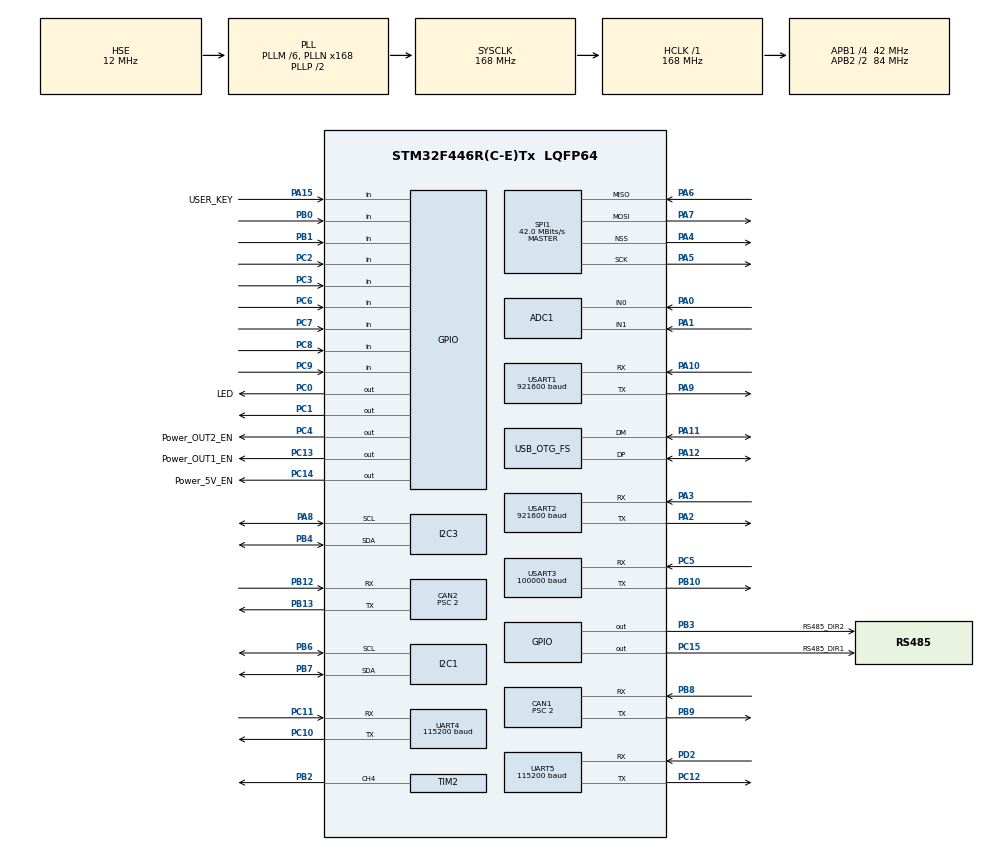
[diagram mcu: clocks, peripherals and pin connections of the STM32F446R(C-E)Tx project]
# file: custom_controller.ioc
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ADC1.Channel-0\#ChannelRegularConversion=ADC_CHANNEL_0
ADC1.NbrOfConversionFlag=1
ADC1.Rank-0\#ChannelRegularConversion=1
ADC1.SamplingTime-0\#ChannelRegularConversion=ADC_SAMPLETIME_3CYCLES
ADC1.master=1
CAN1.ABOM=ENABLE
CAN1.BS1=CAN_BS1_15TQ
CAN1.BS2=CAN_BS2_5TQ
CAN1.CalculateBaudRate=1000000
CAN1.CalculateTimeQuantum=47.61904761904762
CAN1.NART=ENABLE
CAN1.Prescaler=2
CAN1.SJW=CAN_SJW_1TQ
CAN2.ABOM=ENABLE
CAN2.BS1=CAN_BS1_15TQ
CAN2.BS2=CAN_BS2_5TQ
CAN2.CalculateBaudRate=1000000
CAN2.CalculateTimeBit=1000
CAN2.CalculateTimeQuantum=47.61904761904762
CAN2.NART=ENABLE
CAN2.Prescaler=2
CAN2.SJW=CAN_SJW_1TQ
Dma.Request0=USART1_RX
Dma.Request1=USART2_RX
Dma.Request2=UART4_RX
Dma.Request3=UART5_RX
Dma.Request4=USART3_RX
Dma.Request5=UART4_TX
Dma.UART4_RX.2.Direction=DMA_PERIPH_TO_MEMORY
Dma.UART4_RX.2.FIFOMode=DMA_FIFOMODE_DISABLE
Dma.UART4_RX.2.Instance=DMA1_Stream2
Dma.UART4_RX.2.MemDataAlignment=DMA_MDATAALIGN_BYTE
Dma.UART4_RX.2.MemInc=DMA_MINC_ENABLE
Dma.UART4_RX.2.Mode=DMA_NORMAL
Dma.UART4_RX.2.PeriphDataAlignment=DMA_PDATAALIGN_BYTE
Dma.UART4_RX.2.PeriphInc=DMA_PINC_DISABLE
Dma.UART4_RX.2.Priority=DMA_PRIORITY_MEDIUM
Dma.UART4_TX.5.Direction=DMA_MEMORY_TO_PERIPH
Dma.UART4_TX.5.FIFOMode=DMA_FIFOMODE_DISABLE
Dma.UART4_TX.5.Instance=DMA1_Stream4
Dma.UART4_TX.5.MemDataAlignment=DMA_MDATAALIGN_BYTE
Dma.UART4_TX.5.MemInc=DMA_MINC_ENABLE
Dma.UART4_TX.5.Mode=DMA_NORMAL
Dma.UART4_TX.5.PeriphDataAlignment=DMA_PDATAALIGN_BYTE
Dma.UART4_TX.5.PeriphInc=DMA_PINC_DISABLE
Dma.UART4_TX.5.Priority=DMA_PRIORITY_LOW
Dma.UART5_RX.3.Direction=DMA_PERIPH_TO_MEMORY
Dma.UART5_RX.3.FIFOMode=DMA_FIFOMODE_DISABLE
Dma.UART5_RX.3.Instance=DMA1_Stream0
Dma.UART5_RX.3.MemDataAlignment=DMA_MDATAALIGN_BYTE
Dma.UART5_RX.3.MemInc=DMA_MINC_ENABLE
Dma.UART5_RX.3.Mode=DMA_NORMAL
Dma.UART5_RX.3.PeriphDataAlignment=DMA_PDATAALIGN_BYTE
Dma.UART5_RX.3.PeriphInc=DMA_PINC_DISABLE
Dma.UART5_RX.3.Priority=DMA_PRIORITY_MEDIUM
Dma.USART1_RX.0.Direction=DMA_PERIPH_TO_MEMORY
Dma.USART1_RX.0.FIFOMode=DMA_FIFOMODE_DISABLE
Dma.USART1_RX.0.Instance=DMA2_Stream2
Dma.USART1_RX.0.MemDataAlignment=DMA_MDATAALIGN_BYTE
Dma.USART1_RX.0.MemInc=DMA_MINC_ENABLE
Dma.USART1_RX.0.Mode=DMA_NORMAL
Dma.USART1_RX.0.PeriphDataAlignment=DMA_PDATAALIGN_BYTE
Dma.USART1_RX.0.PeriphInc=DMA_PINC_DISABLE
Dma.USART1_RX.0.Priority=DMA_PRIORITY_HIGH
Dma.USART2_RX.1.Direction=DMA_PERIPH_TO_MEMORY
Dma.USART2_RX.1.FIFOMode=DMA_FIFOMODE_DISABLE
Dma.USART2_RX.1.Instance=DMA1_Stream5
Dma.USART2_RX.1.MemDataAlignment=DMA_MDATAALIGN_BYTE
Dma.USART2_RX.1.MemInc=DMA_MINC_ENABLE
Dma.USART2_RX.1.Mode=DMA_NORMAL
Dma.USART2_RX.1.PeriphDataAlignment=DMA_PDATAALIGN_BYTE
Dma.USART2_RX.1.PeriphInc=DMA_PINC_DISABLE
Dma.USART2_RX.1.Priority=DMA_PRIORITY_HIGH
Dma.USART3_RX.4.Direction=DMA_PERIPH_TO_MEMORY
Dma.USART3_RX.4.FIFOMode=DMA_FIFOMODE_DISABLE
Dma.USART3_RX.4.Instance=DMA1_Stream1
Dma.USART3_RX.4.MemDataAlignment=DMA_MDATAALIGN_BYTE
Dma.USART3_RX.4.MemInc=DMA_MINC_ENABLE
Dma.USART3_RX.4.Mode=DMA_NORMAL
Dma.USART3_RX.4.PeriphDataAlignment=DMA_PDATAALIGN_BYTE
Dma.USART3_RX.4.PeriphInc=DMA_PINC_DISABLE
Dma.USART3_RX.4.Priority=DMA_PRIORITY_HIGH
Mcu.Family=STM32F4
Mcu.Name=STM32F446R(C-E)Tx
Mcu.Package=LQFP64
NVIC.CAN1_RX0_IRQn=true\:0\:0\:false\:false\:true\:true\:true\:true
NVIC.CAN1_RX1_IRQn=true\:0\:0\:false\:false\:true\:true\:true\:true
NVIC.CAN2_RX0_IRQn=true\:0\:0\:false\:false\:true\:true\:true\:true
NVIC.CAN2_RX1_IRQn=true\:0\:0\:false\:false\:true\:true\:true\:true
NVIC.DMA1_Stream0_IRQn=true\:0\:0\:false\:false\:true\:false\:true\:true
NVIC.DMA1_Stream1_IRQn=true\:0\:0\:false\:false\:true\:false\:true\:true
NVIC.DMA1_Stream2_IRQn=true\:0\:0\:false\:false\:true\:false\:true\:true
NVIC.DMA1_Stream4_IRQn=true\:0\:0\:false\:false\:true\:false\:true\:true
NVIC.DMA1_Stream5_IRQn=true\:0\:0\:false\:false\:true\:false\:true\:true
NVIC.DMA2_Stream2_IRQn=true\:0\:0\:false\:false\:true\:false\:true\:true
NVIC.OTG_FS_IRQn=true\:0\:0\:false\:false\:true\:false\:true\:true
NVIC.PriorityGroup=NVIC_PRIORITYGROUP_4
NVIC.TIM3_IRQn=true\:2\:0\:true\:false\:true\:true\:true\:true
NVIC.TIM4_IRQn=true\:1\:0\:true\:false\:true\:true\:true\:true
NVIC.TIM5_IRQn=true\:5\:0\:true\:false\:true\:true\:true\:true
NVIC.TIM6_DAC_IRQn=true\:1\:0\:true\:false\:true\:true\:true\:true
NVIC.TIM7_IRQn=true\:0\:0\:false\:false\:true\:true\:true\:true
NVIC.UART4_IRQn=true\:0\:0\:true\:false\:true\:true\:true\:true
NVIC.UART5_IRQn=true\:0\:0\:true\:false\:true\:true\:true\:true
NVIC.USART1_IRQn=true\:0\:0\:false\:false\:true\:true\:true\:true
NVIC.USART2_IRQn=true\:0\:0\:false\:false\:true\:true\:true\:true
NVIC.USART3_IRQn=true\:0\:0\:false\:false\:true\:true\:true\:true
PA0-WKUP.GPIO_Mode=GPIO_MODE_ANALOG
PA0-WKUP.GPIO_PuPd=GPIO_NOPULL
PA0-WKUP.Signal=ADCx_IN0
PA1.GPIO_Mode=GPIO_MODE_ANALOG
PA1.GPIO_PuPd=GPIO_NOPULL
PA1.Signal=ADCx_IN1
PA10.Mode=Asynchronous
PA10.Signal=USART1_RX
PA11.Mode=Device_Only
PA11.Signal=USB_OTG_FS_DM
PA12.Mode=Device_Only
PA12.Signal=USB_OTG_FS_DP
PA13.Mode=Serial_Wire
PA13.Signal=SYS_JTMS-SWDIO
PA14.Mode=Serial_Wire
PA14.Signal=SYS_JTCK-SWCLK
PA15.GPIO_Label=USER_KEY
PA15.Signal=GPIO_Input
PA2.Mode=Asynchronous
PA2.Signal=USART2_TX
PA3.Mode=Asynchronous
PA3.Signal=USART2_RX
PA4.Mode=NSS_Signal_Hard_Output
PA4.Signal=SPI1_NSS
PA5.Mode=Full_Duplex_Master
PA5.Signal=SPI1_SCK
PA6.Mode=Full_Duplex_Master
PA6.Signal=SPI1_MISO
PA7.Mode=Full_Duplex_Master
PA7.Signal=SPI1_MOSI
PA8.GPIO_Pu=GPIO_PULLUP
PA8.Mode=I2C
PA8.Signal=I2C3_SCL
PA9.Mode=Asynchronous
PA9.Signal=USART1_TX
PB0.GPIO_Mode=GPIO_MODE_INPUT
PB0.GPIO_PuPd=GPIO_NOPULL
PB0.Signal=GPIO_Input
PB1.GPIO_Mode=GPIO_MODE_INPUT
PB1.GPIO_PuPd=GPIO_NOPULL
PB1.Signal=GPIO_Input
PB10.Mode=Asynchronous
PB10.Signal=USART3_TX
PB12.Mode=CAN_Activate
PB12.Signal=CAN2_RX
PB13.Mode=CAN_Activate
PB13.Signal=CAN2_TX
PB2.GPIO_ModeDefaultPP=GPIO_MODE_AF_PP
PB2.GPIO_PuPd=GPIO_NOPULL
PB2.GPIO_Speed=GPIO_SPEED_FREQ_LOW
PB2.Signal=S_TIM2_CH4
PB3.GPIO_Label=RS485_DIR2
PB3.GPIO_ModeDefaultOutputPP=GPIO_MODE_OUTPUT_PP
PB3.GPIO_PuPd=GPIO_NOPULL
PB3.GPIO_Speed=GPIO_SPEED_FREQ_LOW
PB3.PinState=GPIO_PIN_RESET
PB3.Signal=GPIO_Output
PB4.GPIO_Pu=GPIO_PULLUP
PB4.Mode=I2C
PB4.Signal=I2C3_SDA
PB5.Signal=S_TIM3_CH2
PB6.GPIO_Pu=GPIO_PULLUP
PB6.Mode=I2C
PB6.Signal=I2C1_SCL
PB7.GPIO_Pu=GPIO_PULLUP
PB7.Mode=I2C
PB7.Signal=I2C1_SDA
PB8.Mode=CAN_Activate
PB8.Signal=CAN1_RX
PB9.Mode=CAN_Activate
PB9.Signal=CAN1_TX
PC0.GPIO_Label=LED
PC0.GPIO_ModeDefaultOutputPP=GPIO_MODE_OUTPUT_PP
PC0.GPIO_PuPd=GPIO_NOPULL
PC0.GPIO_Speed=GPIO_SPEED_FREQ_LOW
PC0.PinState=GPIO_PIN_RESET
PC0.Signal=GPIO_Output
PC1.Signal=GPIO_Output
PC10.Mode=Asynchronous
PC10.Signal=UART4_TX
PC11.Mode=Asynchronous
PC11.Signal=UART4_RX
PC12.Mode=Asynchronous
PC12.Signal=UART5_TX
PC13.GPIO_Label=Power_OUT1_EN
PC13.GPIO_ModeDefaultOutputPP=GPIO_MODE_OUTPUT_PP
PC13.GPIO_PuPd=GPIO_NOPULL
PC13.GPIO_Speed=GPIO_SPEED_FREQ_LOW
PC13.PinState=GPIO_PIN_RESET
PC13.Signal=GPIO_Output
PC14-OSC32_IN.GPIO_Label=Power_5V_EN
PC14-OSC32_IN.GPIO_ModeDefaultOutputPP=GPIO_MODE_OUTPUT_PP
PC14-OSC32_IN.GPIO_PuPd=GPIO_NOPULL
PC14-OSC32_IN.GPIO_Speed=GPIO_SPEED_FREQ_LOW
PC14-OSC32_IN.PinState=GPIO_PIN_RESET
PC14-OSC32_IN.Signal=GPIO_Output
PC15-OSC32_OUT.GPIO_Label=RS485_DIR1
PC15-OSC32_OUT.GPIO_ModeDefaultOutputPP=GPIO_MODE_OUTPUT_PP
PC15-OSC32_OUT.GPIO_PuPd=GPIO_NOPULL
PC15-OSC32_OUT.GPIO_Speed=GPIO_SPEED_FREQ_LOW
PC15-OSC32_OUT.PinState=GPIO_PIN_RESET
PC15-OSC32_OUT.Signal=GPIO_Output
PC2.Signal=GPIO_Input
PC3.Signal=GPIO_Input
PC4.GPIO_Label=Power_OUT2_EN
PC4.Signal=GPIO_Output
PC5.Mode=Asynchronous
PC5.Signal=USART3_RX
PC6.GPIO_PuPd=GPIO_PULLDOWN
PC6.Signal=GPIO_Input
PC7.GPIO_PuPd=GPIO_PULLDOWN
PC7.Signal=GPIO_Input
PC8.GPIO_PuPd=GPIO_PULLDOWN
PC8.Signal=GPIO_Input
PC9.GPIO_PuPd=GPIO_PULLDOWN
PC9.Signal=GPIO_Input
PD2.Mode=Asynchronous
PD2.Signal=UART5_RX
PH0-OSC_IN.Mode=HSE-External-Oscillator
PH0-OSC_IN.Signal=RCC_OSC_IN
PH1-OSC_OUT.Mode=HSE-External-Oscillator
PH1-OSC_OUT.Signal=RCC_OSC_OUT
ProjectManager.HeapSize=0x400
ProjectManager.StackSize=0x800
ProjectManager.TargetToolchain=STM32CubeIDE
RCC.AHBFreq_Value=168000000
RCC.APB1CLKDivider=RCC_HCLK_DIV4
RCC.APB1Freq_Value=42000000
RCC.APB1TimFreq_Value=84000000
RCC.APB2CLKDivider=RCC_HCLK_DIV2
RCC.APB2Freq_Value=84000000
RCC.APB2TimFreq_Value=168000000
RCC.CortexFreq_Value=168000000
RCC.HCLKFreq_Value=168000000
RCC.HSE_VALUE=12000000
RCC.PLLM=6
RCC.PLLN=168
RCC.PLLQ=7
RCC.PLLSAIM=6
RCC.PLLSAIN=96
RCC.PLLSAIP=RCC_PLLSAIP_DIV4
RCC.SYSCLKFreq_VALUE=168000000
RCC.SYSCLKSource=RCC_SYSCLKSOURCE_PLLCLK
RCC.USBFreq_Value=48000000
RCC.VCOOutputFreq_Value=336000000
SH.ADCx_IN0.0=ADC1_IN0,IN0
SH.ADCx_IN1.0=ADC1_IN1,IN1
SH.S_TIM2_CH4.0=TIM2_CH4,PWM Generation4 CH4
SH.S_TIM3_CH2.0=TIM3_CH2
SPI1.BaudRatePrescaler=SPI_BAUDRATEPRESCALER_2
SPI1.CalculateBaudRate=42.0 MBits/s
SPI1.Direction=SPI_DIRECTION_2LINES
SPI1.Mode=SPI_MODE_MASTER
SPI1.VirtualNSS=VM_NSSHARD
SPI1.VirtualType=VM_MASTER
STMicroelectronics.X-CUBE-ALGOBUILD.1.3.0.LibraryCcDSPOoLibraryJjDSPOoLibrary=true
TIM2.Channel-PWM\ Generation4\ CH4=TIM_CHANNEL_4
TIM3.Period=499
TIM3.Prescaler=167
TIM4.Period=166
TIM4.Prescaler=167
TIM5.Period=1679
TIM5.Prescaler=4999
TIM6.Period=333 - 1
TIM6.Prescaler=84 - 1
TIM7.Period=10000 - 1
TIM7.Prescaler=840 - 1
UART4.BaudRate=115200
UART4.VirtualMode=Asynchronous
UART5.BaudRate=115200
UART5.VirtualMode=Asynchronous
USART1.BaudRate=921600
USART1.VirtualMode=VM_ASYNC
USART2.BaudRate=921600
USART2.VirtualMode=VM_ASYNC
USART3.BaudRate=100000
USART3.Mode=MODE_RX
USART3.Parity=PARITY_EVEN
USART3.VirtualMode=VM_ASYNC
USART3.WordLength=WORDLENGTH_9B
USB_DEVICE.CLASS_NAME_FS=CDC
USB_DEVICE.PID_CDC_FS=8738
USB_DEVICE.VID-CDC_FS=1155
USB_DEVICE.VirtualMode-CDC_FS=Cdc
USB_DEVICE.VirtualModeFS=Cdc_FS
USB_OTG_FS.VirtualMode=Device_Only
VP_STMicroelectronics.X-CUBE-ALGOBUILD_VS_DSPOoLibraryJjLibrary_1.3.0_1.3.0.Mode=DSPOoLibraryJjLibrary
VP_TIM10_VS_ClockSourceINT.Mode=Enable_Timer
VP_TIM3_VS_ClockSourceINT.Mode=Internal
VP_TIM4_VS_ClockSourceINT.Mode=Internal
VP_TIM5_VS_ClockSourceINT.Mode=Internal
VP_TIM6_VS_ClockSourceINT.Mode=Enable_Timer
VP_TIM7_VS_ClockSourceINT.Mode=Enable_Timer
VP_USB_DEVICE_VS_USB_DEVICE_CDC_FS.Mode=CDC_FS
board=custom

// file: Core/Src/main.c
/* USER CODE BEGIN Header */
/**
  ******************************************************************************
  * @file           : main.c
  * @brief          : Main program body
  ******************************************************************************
  * @attention
  *
  * Copyright (c) 2024 STMicroelectronics.
  * All rights reserved.
  *
  * This software is licensed under terms that can be found in the LICENSE file
  * in the root directory of this software component.
  * If no LICENSE file comes with this software, it is provided AS-IS.
  *
  ******************************************************************************
  */
/* USER CODE END Header */
#include "main.h"
#include "adc.h"
#include "can.h"
#include "dma.h"
#include "i2c.h"
#include "spi.h"
#include "tim.h"
#include "usart.h"
#include "usb_device.h"
#include "gpio.h"

/* USER CODE BEGIN Includes */
#include "User_Main.h"
/* USER CODE END Includes */

void SystemClock_Config(void);

int main(void)
{

  /* MCU Configuration--------------------------------------------------------*/

  /* Reset of all peripherals, Initializes the Flash interface and the Systick. */
  HAL_Init();

  /* Configure the system clock */
  SystemClock_Config();

  /* Initialize all configured peripherals */
  MX_GPIO_Init();
  MX_DMA_Init();
  MX_CAN1_Init();
  MX_CAN2_Init();
  MX_SPI1_Init();
  MX_UART4_Init();
  MX_UART5_Init();
  MX_USART1_UART_Init();
  MX_ADC1_Init();
  MX_I2C1_Init();
  MX_I2C3_Init();
  MX_USART2_UART_Init();
  MX_USB_DEVICE_Init();
  MX_TIM2_Init();
  MX_TIM4_Init();
  MX_TIM5_Init();
  MX_TIM10_Init();
  MX_TIM3_Init();
  MX_USART3_UART_Init();
  MX_TIM6_Init();
  MX_TIM7_Init();
  /* USER CODE BEGIN 2 */
  User_setup();
  /* USER CODE END 2 */

  /* Infinite loop */
  /* USER CODE BEGIN WHILE */
  while (1)
  {
    User_loop();
    /* USER CODE END WHILE */

  }
}

void SystemClock_Config(void)
{
  RCC_OscInitTypeDef RCC_OscInitStruct = {0};
  RCC_ClkInitTypeDef RCC_ClkInitStruct = {0};

  /** Configure the main internal regulator output voltage
  */
  __HAL_RCC_PWR_CLK_ENABLE();
  __HAL_PWR_VOLTAGESCALING_CONFIG(PWR_REGULATOR_VOLTAGE_SCALE1);

  /** Initializes the RCC Oscillators according to the specified parameters
  * in the RCC_OscInitTypeDef structure.
  */
  RCC_OscInitStruct.OscillatorType = RCC_OSCILLATORTYPE_HSE;
  RCC_OscInitStruct.HSEState = RCC_HSE_ON;
  RCC_OscInitStruct.PLL.PLLState = RCC_PLL_ON;
  RCC_OscInitStruct.PLL.PLLSource = RCC_PLLSOURCE_HSE;
  RCC_OscInitStruct.PLL.PLLM = 6;
  RCC_OscInitStruct.PLL.PLLN = 168;
  RCC_OscInitStruct.PLL.PLLP = RCC_PLLP_DIV2;
  RCC_OscInitStruct.PLL.PLLQ = 7;
  RCC_OscInitStruct.PLL.PLLR = 2;
  if (HAL_RCC_OscConfig(&RCC_OscInitStruct) != HAL_OK)
  {
    Error_Handler();
  }

  /** Initializes the CPU, AHB and APB buses clocks
  */
  RCC_ClkInitStruct.ClockType = RCC_CLOCKTYPE_HCLK|RCC_CLOCKTYPE_SYSCLK
                              |RCC_CLOCKTYPE_PCLK1|RCC_CLOCKTYPE_PCLK2;
  RCC_ClkInitStruct.SYSCLKSource = RCC_SYSCLKSOURCE_PLLCLK;
  RCC_ClkInitStruct.AHBCLKDivider = RCC_SYSCLK_DIV1;
  RCC_ClkInitStruct.APB1CLKDivider = RCC_HCLK_DIV4;
  RCC_ClkInitStruct.APB2CLKDivider = RCC_HCLK_DIV2;

  if (HAL_RCC_ClockConfig(&RCC_ClkInitStruct, FLASH_LATENCY_5) != HAL_OK)
  {
    Error_Handler();
  }
}

void Error_Handler(void)
{
  __disable_irq();
  while (1)
  {
  }
}
